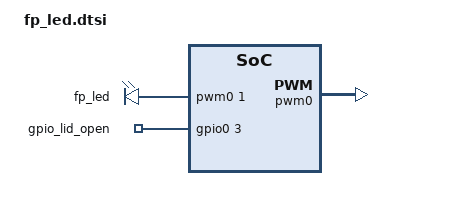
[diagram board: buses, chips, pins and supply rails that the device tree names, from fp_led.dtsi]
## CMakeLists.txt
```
# Copyright 2024 The ChromiumOS Authors
# Use of this source code is governed by a BSD-style license that can be
# found in the LICENSE file.

cmake_minimum_required(VERSION 3.13.1)
find_package(Zephyr REQUIRED HINTS "${ZEPHYR_BASE}")
project(fpsensor_task_test)

target_include_directories(app PUBLIC ${PLATFORM_EC}/common)
zephyr_include_directories("${CMAKE_CURRENT_SOURCE_DIR}/include")

target_sources(app PRIVATE src/mock_fingerprint_algorithm.c)
target_sources_ifdef(CONFIG_LINK_TEST_SUITE_FINGERPRINT_CAPTURE app PRIVATE
	src/fpsensor_capture.cc)
target_sources_ifdef(CONFIG_LINK_TEST_SUITE_FINGERPRINT_ENROLL app PRIVATE
	src/fpsensor_enroll.cc)
target_sources_ifdef(CONFIG_LINK_TEST_SUITE_FINGERPRINT_FINGER_PRESENCE app PRIVATE
	src/fpsensor_finger_presence.cc)
target_sources_ifdef(CONFIG_LINK_TEST_SUITE_FINGERPRINT_GET_FRAME app PRIVATE
	src/fpsensor_get_frame.cc)
target_sources_ifdef(CONFIG_LINK_TEST_SUITE_FINGERPRINT_INIT app PRIVATE
	src/fpsensor_init.cc)
target_sources_ifdef(CONFIG_LINK_TEST_SUITE_FINGERPRINT_MATCH app PRIVATE
	src/fpsensor_match.cc)
target_sources_ifdef(CONFIG_LINK_TEST_SUITE_FINGERPRINT_SHIM app PRIVATE
	src/fpsensor_shim.cc)
target_sources_ifdef(CONFIG_LINK_TEST_SUITE_FINGERPRINT_STATE app PRIVATE
	src/fpsensor_state.cc)
target_sources_ifdef(CONFIG_LINK_TEST_SUITE_FINGERPRINT_TEMPLATE app PRIVATE
	src/fpsensor_template.cc
	${PLATFORM_EC}/zephyr/mock/fpsensor_crypto_mock.cc)
target_sources_ifdef(CONFIG_LINK_TEST_SUITE_FINGERPRINT_UTILS app PRIVATE
	src/fpsensor_utils.cc)
target_sources_ifdef(CONFIG_LINK_TEST_SUITE_FINGERPRINT_DEBUG app PRIVATE
	src/fpsensor_debug.cc)
target_sources_ifdef(CONFIG_LINK_TEST_SUITE_FINGERPRINT_COMMANDS app PRIVATE
	src/fpsensor_vendor_command.cc)
target_sources_ifdef(CONFIG_LINK_TEST_SUITE_FINGERPRINT_ASCP app PRIVATE
	src/fpsensor_ascp.cc)
target_sources_ifdef(CONFIG_LINK_TEST_SUITE_FINGERPRINT_IMAGE_FRAME_PARAMS app PRIVATE
	src/fpsensor_image_frame_params.cc)
target_sources_ifdef(CONFIG_LINK_TEST_SUITE_FINGERPRINT_BTN_IGN_OUT app PRIVATE
	src/fpsensor_btn_ign_out.cc)
target_sources_ifdef(CONFIG_LINK_TEST_SUITE_FINGERPRINT_LED app PRIVATE
	src/fpsensor_led.cc)
target_sources_ifdef(CONFIG_LINK_TEST_SUITE_FINGERPRINT_AUTH_COMMANDS app PRIVATE
	src/fpsensor_auth_commands.cc)
target_sources_ifdef(CONFIG_NPCX_OTP_KEY app PRIVATE
	${PLATFORM_EC}/zephyr/shim/chip/npcx/otp_key.c
	${PLATFORM_EC}/zephyr/mock/otpi_mock.c)

add_subdirectory(${PLATFORM_EC}/zephyr/test/test_utils test_utils)
```

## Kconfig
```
# Copyright 2024 The ChromiumOS Authors
# Use of this source code is governed by a BSD-style license that can be
# found in the LICENSE file.

config LINK_TEST_SUITE_FINGERPRINT_CAPTURE
	bool "Link fingerprint capture tests"
	help
	  Link and execute fingerprint subsystem tests that focus
	  on finger capture.

config LINK_TEST_SUITE_FINGERPRINT_ENROLL
	bool "Link fingerprint enroll tests"
	help
	  Link and execute fingerprint subsystem tests that focus
	  on template enrollment.

config LINK_TEST_SUITE_FINGERPRINT_FINGER_PRESENCE
	bool "Link fingerprint finger presence tests"
	help
	  Link and execute fingerprint subsystem tests that focus
	  on finger presence.

config LINK_TEST_SUITE_FINGERPRINT_GET_FRAME
	bool "Link fingerprint get frame tests"
	help
	  Link and execute fingerprint subsystem tests that focus
	  on the get_frame functionality, verifying memory bounds,
	  buffer offsets, and hardware state.

config LINK_TEST_SUITE_FINGERPRINT_INIT
	bool "Link fingerprint init tests"
	help
	  Link and execute fingerprint subsystem tests that focus
	  on initializing TPM seed and context.

config LINK_TEST_SUITE_FINGERPRINT_MATCH
	bool "Link fingerprint match tests"
	help
	  Link and execute fingerprint subsystem tests that focus
	  on finger matching.

config LINK_TEST_SUITE_FINGERPRINT_SHIM
	bool "Link fingerprint shim tests"
	help
	  Link and execute fingerprint subsystem tests that focus
	  on fpsensor shim.

config LINK_TEST_SUITE_FINGERPRINT_STATE
	bool "Link fingerprint state tests"
	help
	  Link and execute fingerprint subsystem tests that focus
	  on fpsensor state.

config LINK_TEST_SUITE_FINGERPRINT_TEMPLATE
	bool "Link fingerprint template tests"
	help
	  Link and execute fingerprint subsystem tests that focus
	  on finger templates.

config LINK_TEST_SUITE_FINGERPRINT_UTILS
	bool "Link fingerprint utils tests"
	help
	  Link and execute fingerprint subsystem tests that focus
	  on finger utils.

config LINK_TEST_SUITE_FINGERPRINT_DEBUG
	bool "Link fingerprint debug tests"
	help
	  Link and execute fingerprint subsystem tests that focus
	  on finger debug.

config LINK_TEST_SUITE_FINGERPRINT_COMMANDS
	bool "Link fingerprint commands tests"
	help
	  Link and execute fingerprint subsystem tests that focus
	  on fingerprint host and console commands.

config LINK_TEST_SUITE_FINGERPRINT_ASCP
	bool "Link fingerprint ASCP tests"
	help
	  Link and execute fingerprint subsystem tests that focus
	  on ASCP.

config LINK_TEST_SUITE_FINGERPRINT_FRAME_SIZE
	bool "Link fingerprint frame size tests"
	help
	  Link and execute fingerprint subsystem tests that focus
	  on finger frame size.

config LINK_TEST_SUITE_FINGERPRINT_BTN_IGN_OUT
	bool "Link fingerprint btn ign out tests"
	help
	  Link and execute fingerprint subsystem tests that focus
	  on btn ign out.

config LINK_TEST_SUITE_FINGERPRINT_LED
	bool "Link fingerprint led tests"
	select HAS_PM
	help
	  Link and execute fingerprint subsystem tests that focus
	  on led.

config LINK_TEST_SUITE_FINGERPRINT_AUTH_COMMANDS
	bool "Link fingerprint auth commands tests"
	help
	  Link and execute fingerprint subsystem tests that focus
	  on fingerprint auth commands.

config LINK_TEST_SUITE_FINGERPRINT_CRYPTO
	bool "Link fingerprint crypto tests"
	help
	  Link and execute fingerprint subsystem crypto tests.

config LINK_TEST_SUITE_FINGERPRINT_AUTH_CRYPTO_STATEFUL
	bool "Link fingerprint stateful auth crypto tests"
	help
	  Link and execute fingerprint stateful auth crypto tests.

config LINK_TEST_SUITE_FINGERPRINT_AUTH_CRYPTO_STATELESS
	bool "Link fingerprint stateless auth crypto tests"
	help
	  Link and execute fingerprint stateless auth crypto tests.

config OTP_KEY
	bool "Enable OTP key mock support"
	default n

config EC_HOST_CMD_HANDLER_TX_BUFFER_SIZE
	int "HC TX buffer size"
	default 544

source "Kconfig.zephyr"
```

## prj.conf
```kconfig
# Copyright 2024 The ChromiumOS Authors
# Use of this source code is governed by a BSD-style license that can be
# found in the LICENSE file.

CONFIG_TEST=y
CONFIG_ZTEST=y
CONFIG_EMUL=y
CONFIG_FLASH=y
CONFIG_GPIO=y

CONFIG_UART_NATIVE_PTY_0_ON_STDINOUT=y

CONFIG_CPP=y
CONFIG_STD_CPP23=y
CONFIG_REQUIRES_FULL_LIBCPP=y

CONFIG_CROS_EC=y
CONFIG_PLATFORM_EC=y
CONFIG_SHIMMED_TASKS=y

CONFIG_COMMON_LIBC_MALLOC=y
CONFIG_COMMON_LIBC_MALLOC_ARENA_SIZE=2048
CONFIG_BORINGSSL_CRYPTO=y

CONFIG_PLATFORM_EC_RANDOM=y
CONFIG_PLATFORM_EC_FINGERPRINT=y
CONFIG_PLATFORM_EC_ROLLBACK=y
CONFIG_PLATFORM_EC_ROLLBACK_UPDATE=y
CONFIG_PLATFORM_EC_ROLLBACK_SECRET_SIZE=32
CONFIG_PLATFORM_EC_SHA256_SW=y
CONFIG_PLATFORM_EC_SHA256_UNROLLED=y
CONFIG_PLATFORM_EC_BACKLIGHT_LID=n
CONFIG_PLATFORM_EC_CONSOLE_CMD_CHARGEN=n
CONFIG_PLATFORM_EC_SWITCH=n
CONFIG_PLATFORM_EC_FLASH_SIZE_BYTES=0x200000
CONFIG_PLATFORM_EC_HOSTCMD=y

CONFIG_FINGERPRINT_SUBSYSTEM=y
CONFIG_FINGERPRINT_SENSOR=y

CONFIG_FP_ALGORITHM_TEMPLATE_SIZE=32
```

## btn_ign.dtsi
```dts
/* Copyright 2026 The ChromiumOS Authors
 * Use of this source code is governed by a BSD-style license that can be
 * found in the LICENSE file.
 */

#include "boards/native_sim.overlay"

/ {
	aliases {
		gpio-btn-ign-out = &gpio_btn_ign_out;
	};

	gpio-outputs {
		compatible = "gpio-leds";

		gpio_btn_ign_out: gpio_btn_ign_out {
			gpios = <&gpio0 3 GPIO_ACTIVE_HIGH>;
		};
	};
};
```

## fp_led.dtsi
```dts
/* Copyright 2026 The ChromiumOS Authors
 * Use of this source code is governed by a BSD-style license that can be
 * found in the LICENSE file.
 */

#include "boards/native_sim.overlay"
#include <zephyr/dt-bindings/pwm/pwm.h>

/{
	pwm0: pwm@6 {
		compatible = "cros,pwm-mock";
		reg = <6 2>;
		#pwm-cells = <3>;
		status = "okay";
	};

	pwmleds {
		compatible = "pwm-leds";

		fp_led: fp_led {
			pwms = <&pwm0 1 PWM_MSEC(20) PWM_POLARITY_NORMAL>;
		};
	};

	gpio-keys {
		compatible = "gpio-keys";

		gpio_lid_open: gpio_lid_open {
			gpios = <&gpio0 3 (GPIO_PULL_UP | GPIO_ACTIVE_HIGH)>;
		};
	};

	power-states {
		suspend_to_idle: suspend_to_idle {
			compatible = "zephyr,power-state";
			power-state-name = "suspend-to-idle";
			substate-id = <0>;
			min-residency-us = <500>;
		};
	};

	aliases {
		pwm-fp-led = &fp_led;
		gpio-lid-open = &gpio_lid_open;
	};
};
```

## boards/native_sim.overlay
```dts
/* Copyright 2023 The ChromiumOS Authors
 * Use of this source code is governed by a BSD-style license that can be
 * found in the LICENSE file.
 */

#include <board-overlays/native_sim.dts>
#include <dt-bindings/gpio_defines.h>
#include <cros/binman.dtsi>

/* RAW image includes additional metadata */
#define FP_SIMULATOR_RAW_IMAGE_PROPS \
	width = <160>; \
	height = <160>; \
	bits-per-pixel = <8>; \
	frame-size = <26260>; \
	image-data-offset-bytes = <400>; \
	v4l2-pixel-format = "V4L2_PIX_FMT_GREY";

/* REAL image is just pixel data (160 * 160) */
#define FP_SIMULATOR_REAL_IMAGE_PROPS \
	width = <160>; \
	height = <160>; \
	bits-per-pixel = <8>; \
	/* Sensor real image size: (160*160) */ \
	frame-size = <25600>; \
	image-data-offset-bytes = <400>; \
	v4l2-pixel-format = "V4L2_PIX_FMT_GREY";

/ {
	chosen {
		cros-ec,flash-controller = &cros_flash;
		cros-fp,fingerprint-sensor = &fpsensor_sim;
	};

	aliases {
		gpio-wp = &ec_wp_l;
	};

	named-gpios {
		compatible = "named-gpios";

		ec_wp_l: write-protect {
			gpios = <&gpio0 0 GPIO_INPUT>;
		};

		fp_sensor_sel: fp_sensor_sel {
			gpios = <&gpio0 1 GPIO_INPUT>;
		};

		div_highside: div_highside {
			gpios = <&gpio0 2 GPIO_OUTPUT_HIGH>;
		};

		gpio_btn_ign_out: gpio_btn_ign_out {
			gpios = <&gpio0 3 GPIO_OUTPUT_INACTIVE>;
		};
	};

	cros_flash: cros-flash {
		compatible = "cros-ec,flash-emul";
	};

	fpsensor_sim: fpsensor-sim {
		compatible = "cros-ec,fingerprint-sensor-sim";
		configs {
			compatible = "fingerprint-image-frame-params";
			config0 {
				FP_SIMULATOR_RAW_IMAGE_PROPS
				capture-type = "FINGERPRINT_CAPTURE_TYPE_VENDOR_FORMAT";
			};
			config1 {
				FP_SIMULATOR_REAL_IMAGE_PROPS
				capture-type = "FINGERPRINT_CAPTURE_TYPE_SIMPLE_IMAGE";
			};
			config2 {
				FP_SIMULATOR_REAL_IMAGE_PROPS
				capture-type = "FINGERPRINT_CAPTURE_TYPE_PATTERN0";
			};
			config3 {
				FP_SIMULATOR_REAL_IMAGE_PROPS
				capture-type = "FINGERPRINT_CAPTURE_TYPE_PATTERN1";
			};
			config4 {
				FP_SIMULATOR_RAW_IMAGE_PROPS
				capture-type = "FINGERPRINT_CAPTURE_TYPE_QUALITY_TEST";
			};
			config5 {
				FP_SIMULATOR_REAL_IMAGE_PROPS
				capture-type = "FINGERPRINT_CAPTURE_TYPE_RESET_TEST";
			};
		};
	};
};

&gpio0 {
	ngpios = <4>;
};

&flash0 {
	partitions {
		compatible = "fixed-partitions";
		#address-cells = <1>;
		#size-cells = <1>;

		/* Rollback region must have erase unit size. */
		rollback0: partition@100000 {
			label = "rollback0";
			reg = <0x100000 DT_SIZE_K(4)>;
		};

		rollback1: partition@101000 {
			label = "rollback1";
			reg = <0x101000 DT_SIZE_K(4)>;
		};
	};
};
```

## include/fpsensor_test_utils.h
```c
/* Copyright 2026 The ChromiumOS Authors
 * Use of this source code is governed by a BSD-style license that can be
 * found in the LICENSE file.
 */

#ifndef PLATFORM_EC_ZEPHYR_TEST_FINGERPRINT_TASK_INCLUDE_FPSENSOR_TEST_UTILS_H_
#define PLATFORM_EC_ZEPHYR_TEST_FINGERPRINT_TASK_INCLUDE_FPSENSOR_TEST_UTILS_H_

#include <zephyr/devicetree.h>
#include <zephyr/kernel.h>
#include <zephyr/sys/printk.h>
#include <zephyr/sys/util.h>
#include <zephyr/ztest_assert.h>

#include <algorithm>
#include <array>
#include <drivers/fingerprint.h>
#include <drivers/fingerprint_sim.h>
#include <flash.h>
#include <fpsensor/fpsensor.h>
#include <fpsensor/fpsensor_image_frame_params.h>
#include <fpsensor/fpsensor_modes.h>
#include <host_command.h>
#include <rollback.h>
#include <rollback_private.h>
#include <string_view>
#include <utility>

class FpSimulator {
    public:
	constexpr explicit FpSimulator(const device *dev) noexcept : dev_(dev)
	{
	}

	constexpr operator const device *() const noexcept
	{
		return dev_;
	}

	template <typename Fn> void update(Fn &&mutate) const
	{
		fingerprint_sensor_state state{};
		fingerprint_get_state(dev_, &state);
		mutate(state);
		fingerprint_set_state(dev_, &state);
	}

	void reset() const
	{
		fingerprint_sensor_state state = {
			.bad_pixels = 0,
			.maintenance_ran = false,
			.detect_mode = false,
			.low_power_mode = false,
			.finger_state = FINGERPRINT_FINGER_STATE_NONE,
			.init_result = 0,
			.deinit_result = 0,
			.config_result = 0,
			.get_info_result = 0,
			.acquire_image_result = FINGERPRINT_SENSOR_SCAN_GOOD,
			.last_acquire_image_mode = -1,
		};
		fingerprint_set_state(dev_, &state);
	}

    private:
	const device *dev_;
};

inline constexpr FpSimulator fp_sim{ DEVICE_DT_GET(
	DT_CHOSEN(cros_fp_fingerprint_sensor)) };

inline constexpr size_t kImageSize = MAX_FROM_LIST(
	LISTIFY(NUM_IMAGE_CAPTURE_TYPES, FINGERPRINT_SENSOR_FRAME_SIZE, (, ),
		DT_CHOSEN(cros_fp_fingerprint_sensor)));

inline constexpr uintptr_t kRollback0Addr =
	DT_REG_ADDR(DT_NODELABEL(rollback0));
inline constexpr size_t kRollback0Size = DT_REG_SIZE(DT_NODELABEL(rollback0));
inline constexpr uintptr_t kRollback1Addr =
	DT_REG_ADDR(DT_NODELABEL(rollback1));
inline constexpr size_t kRollback1Size = DT_REG_SIZE(DT_NODELABEL(rollback1));

/* The fake TPM seed is "very_secret_32_bytes_of_tpm_seed" */
inline constexpr std::array<uint8_t, FP_CONTEXT_TPM_BYTES> kDefaultTpmSeed = {
	0x76, 0x65, 0x72, 0x79, 0x5f, 0x73, 0x65, 0x63, 0x72, 0x65, 0x74,
	0x5f, 0x33, 0x32, 0x5f, 0x62, 0x79, 0x74, 0x65, 0x73, 0x5f, 0x6f,
	0x66, 0x5f, 0x74, 0x70, 0x6d, 0x5f, 0x73, 0x65, 0x65, 0x64
};

/* The fake UserID is "i_m_a_fake_user_id_used_for_test" */
inline constexpr std::array<uint32_t, FP_CONTEXT_USERID_WORDS> kDefaultUserId = {
	0x5f6d5f69, 0x61665f61, 0x755f656b, 0x5f726573,
	0x755f6469, 0x5f646573, 0x5f726f66, 0x74736574
};

template <typename Fn> inline void update_sim_state(Fn &&mutate)
{
	fp_sim.update(std::forward<Fn>(mutate));
}

inline void reset_sim_state()
{
	fp_sim.reset();
}

template <typename PreEntropyFn = decltype([] {})>
inline void init_test_rollback(PreEntropyFn &&pre_entropy = {})
{
	static constexpr std::string_view kEntropy = "some_rollback_entropy";
	const rollback_data data = {
		.id = 0,
		.rollback_min_version = 0,
#ifdef CONFIG_PLATFORM_EC_ROLLBACK_SECRET_SIZE
		.secret = { 0 },
#endif
		.cookie = CROS_EC_ROLLBACK_COOKIE,
	};

	zassert_ok(crec_flash_erase(kRollback0Addr, kRollback0Size));
	zassert_ok(crec_flash_write(kRollback0Addr, sizeof(data),
				    reinterpret_cast<const char *>(&data)));

	zassert_ok(crec_flash_erase(kRollback1Addr, kRollback1Size));
	zassert_ok(crec_flash_write(kRollback1Addr, sizeof(data),
				    reinterpret_cast<const char *>(&data)));

	pre_entropy();

	rollback_add_entropy(reinterpret_cast<const uint8_t *>(kEntropy.data()),
			     kEntropy.size());
}

inline uint32_t get_fp_mode()
{
	ec_params_fp_mode params = {
		.mode = FP_MODE_DONT_CHANGE,
	};
	ec_response_fp_mode response{};
	zassert_ok(ec_cmd_fp_mode(nullptr, &params, &response));
	return response.mode;
}

inline int get_fp_info_v3(FpSensorInfoBuffer &buf,
			  size_t size = sizeof(FpSensorInfoBuffer))
{
	return ec_cmd_fp_info_v3(nullptr, &buf.header, size);
}

inline uint32_t set_fp_mode(uint32_t mode)
{
	ec_params_fp_mode params = {
		.mode = mode,
	};
	ec_response_fp_mode response{};
	zassert_ok(ec_cmd_fp_mode(nullptr, &params, &response));
	k_msleep(1);
	return response.mode;
}

inline void set_default_tpm_seed()
{
	ec_params_fp_seed fp_seed_params = {
		.struct_version = FP_TEMPLATE_FORMAT_VERSION,
		.reserved = 0,
	};
	std::ranges::copy(kDefaultTpmSeed, fp_seed_params.seed);
	zassert_ok(ec_cmd_fp_seed(nullptr, &fp_seed_params));
}

inline void reset_test_fp_context(
	std::span<const uint32_t, FP_CONTEXT_USERID_WORDS> userid =
		kDefaultUserId)
{
	ec_params_fp_context_v1 fp_context_params = {
		.action = FP_CONTEXT_ASYNC,
	};
	std::ranges::copy(userid, fp_context_params.userid);
	zassert_ok(ec_cmd_fp_context_v1(nullptr, &fp_context_params));
	k_msleep(1);

	fp_context_params.action = FP_CONTEXT_GET_RESULT;
	zassert_ok(ec_cmd_fp_context_v1(nullptr, &fp_context_params));
}

extern "C" inline ec_status test_send_host_command(int command, int version,
						   const void *params,
						   int params_size, void *resp,
						   int resp_size)
{
	host_cmd_handler_args args{};

	args.command = command;
	args.version = version;
	args.params = params;
	args.params_size = params_size;
	args.response = resp;
	args.response_max = resp_size;
	args.response_size = 0;

	return static_cast<ec_status>(host_command_process(&args));
}

template <typename Params, typename Resp>
inline ec_status send_host_cmd(int command, int version, const Params &params,
			       Resp &resp)
{
	return test_send_host_command(command, version, &params, sizeof(params),
				      &resp, sizeof(resp));
}

template <typename Params>
inline ec_status send_host_cmd_req(int command, int version,
				   const Params &params)
{
	return test_send_host_command(command, version, &params, sizeof(params),
				      nullptr, 0);
}

template <typename Resp>
inline ec_status send_host_cmd_resp(int command, int version, Resp &resp)
{
	return test_send_host_command(command, version, nullptr, 0, &resp,
				      sizeof(resp));
}

#define FP_SIMULATOR_IMAGE_FRAME_PARAM_INITIALIZER(idx, node_id)            \
	{                                                                   \
		.frame_size = FINGERPRINT_SENSOR_FRAME_SIZE(idx, node_id),  \
		.image_data_offset_bytes =                                  \
			FINGERPRINT_SENSOR_IMAGE_OFFSET(idx, node_id),      \
		.pixel_format =                                             \
			FINGERPRINT_SENSOR_V4L2_PIXEL_FORMAT(idx, node_id), \
		.width = FINGERPRINT_SENSOR_RES_X(idx, node_id),            \
		.height = FINGERPRINT_SENSOR_RES_Y(idx, node_id),           \
		.bpp = FINGERPRINT_SENSOR_RES_BPP(idx, node_id),            \
		.fp_capture_type =                                          \
			FINGERPRINT_SENSOR_CAPTURE_TYPE(idx, node_id),      \
		.reserved = 0,                                              \
	}

#if DT_NODE_EXISTS(DT_NODELABEL(fpsensor_sim))
inline constexpr auto kDefaultSimImageFrameParams =
	std::to_array<fingerprint_image_frame_params>(
		{ LISTIFY(NUM_IMAGE_CAPTURE_TYPES,
			  FP_SIMULATOR_IMAGE_FRAME_PARAM_INITIALIZER, (, ),
			  DT_NODELABEL(fpsensor_sim)) });
#endif

class FpImageFrameParamsCacheTestHelper {
    public:
	FpImageFrameParamsCacheTestHelper() = delete;

	static bool set_frame_size(FpImageFrameParamsCache &cache,
				   fp_capture_type capture_type, uint32_t size)
	{
		const auto valid_type = FpCaptureType::create(capture_type);
		if (!valid_type.has_value()) {
			printk("Error: Invalid capture type %d\n",
			       capture_type);
			return false;
		}
		cache.frame_params_[valid_type->raw()].frame_size_bytes = size;
		return true;
	}
};

#endif /* PLATFORM_EC_ZEPHYR_TEST_FINGERPRINT_TASK_INCLUDE_FPSENSOR_TEST_UTILS_H_ \
	*/
```

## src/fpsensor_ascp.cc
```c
/* Copyright 2026 The ChromiumOS Authors
 * Use of this source code is governed by a BSD-style license that can be
 * found in the LICENSE file.
 */

#include "common.h"
#include "console.h"
#include "fpsensor/fpsensor_auth_crypto.h"
#include "fpsensor_test_utils.h"
#include "openssl/mem.h"
#include "system.h"

#include <zephyr/drivers/emul.h>
#include <zephyr/fff.h>
#include <zephyr/ztest.h>

#include <algorithm>
#include <array>
extern "C" {
#include <ascp/ascp.h>
}
#include <ec_commands.h>
#include <fpsensor/fpsensor.h>
#include <fpsensor/fpsensor_state.h>
#include <fpsensor/fpsensor_state_driver.h>
#include <fpsensor/fpsensor_utils.h>
#include <fpsensor_driver.h>
#include <host_command.h>
#include <mkbp_event.h>
#include <ranges>

FAKE_VALUE_FUNC(int, mkbp_send_event, uint8_t);

namespace
{

constexpr std::array<uint8_t, FP_ELLIPTIC_CURVE_PRIVATE_KEY_LEN> kSkF = {
	0x64, 0xfb, 0xd5, 0x8f, 0x6b, 0x57, 0x2a, 0x41, 0xef, 0x00, 0x0e,
	0x18, 0x92, 0xf8, 0xb5, 0x52, 0xc7, 0x41, 0x34, 0x35, 0xb1, 0xce,
	0x7c, 0x11, 0xfc, 0xf5, 0xa5, 0x94, 0x97, 0xaa, 0xc4, 0x91
};

constexpr std::array<uint8_t, FP_ASCP_KEY_SIZE> kPkF = {
	0x04, 0x48, 0x04, 0x5c, 0x21, 0x5b, 0x8d, 0x9b, 0x23, 0x31, 0x95,
	0x0e, 0x2a, 0x8d, 0x8f, 0x26, 0x22, 0x66, 0xe9, 0x59, 0xc2, 0x37,
	0xc9, 0x4f, 0x94, 0x73, 0x27, 0xc2, 0xb1, 0x11, 0xa0, 0x01, 0x78,
	0x13, 0x2f, 0x08, 0x9e, 0x94, 0xe7, 0x6d, 0x58, 0x76, 0xa1, 0x1a,
	0x20, 0xda, 0x0c, 0xc1, 0xef, 0x91, 0xaf, 0xb1, 0x5d, 0x48, 0x81,
	0x1b, 0x6b, 0xe1, 0x6e, 0xc0, 0xd5, 0xfb, 0x9d, 0x69, 0x82
};

constexpr std::array<uint8_t, FP_ELLIPTIC_CURVE_PRIVATE_KEY_LEN> kSkG = {
	0x2e, 0xdd, 0x7a, 0x67, 0x2f, 0x22, 0x21, 0x5c, 0x23, 0x80, 0xf0,
	0x80, 0x29, 0x5c, 0x6d, 0x95, 0xe9, 0x0b, 0x31, 0x9c, 0x17, 0xc1,
	0xc6, 0xcc, 0xe3, 0xbe, 0x9b, 0x7c, 0xd7, 0x2a, 0x18, 0x3f
};

constexpr std::array<uint8_t, FP_ASCP_KEY_SIZE> kPkG = {
	0x04, 0x65, 0xf5, 0xd4, 0x79, 0x82, 0x7e, 0xc1, 0xaf, 0x28, 0x2e,
	0x4b, 0xd0, 0xa6, 0xcb, 0xf4, 0xf4, 0xf5, 0x16, 0x63, 0xa6, 0x85,
	0x40, 0xdc, 0xa4, 0x26, 0xe8, 0x63, 0xc3, 0xa8, 0x52, 0xd3, 0x25,
	0x42, 0x8d, 0xd4, 0x7d, 0x85, 0x30, 0x6c, 0x16, 0x6e, 0x99, 0x24,
	0x65, 0x5c, 0x6d, 0x9b, 0x04, 0xfe, 0xfb, 0x83, 0x49, 0x9d, 0xa9,
	0x2a, 0xae, 0x75, 0x3e, 0x79, 0xdc, 0xa1, 0x80, 0x6e, 0x6e
};

std::array<uint8_t, FP_ELLIPTIC_CURVE_PRIVATE_KEY_LEN> ascp_get_sk_f_custom_sk_f;
int ascp_get_sk_f_custom_ret;

ec_params_fp_ascp_establish make_establish_params()
{
	ec_params_fp_ascp_establish params{};
	std::ranges::copy(kPkG, params.pk_g);
	return params;
}

void reset(void *data)
{
	ARG_UNUSED(data);

	ascp_get_sk_f_custom_ret = 0;
	ascp_get_sk_f_custom_sk_f = kSkF;
}

} /* namespace */

extern "C" int ascp_get_claim(ec_response_fp_ascp_claim *res)
{
	return EC_SUCCESS;
}

extern "C" int ascp_get_sk_f(uint8_t *buffer, size_t len)
{
	zassert_equal(len, FP_ELLIPTIC_CURVE_PRIVATE_KEY_LEN);
	if (ascp_get_sk_f_custom_ret != 0) {
		return ascp_get_sk_f_custom_ret;
	}
	std::ranges::copy(ascp_get_sk_f_custom_sk_f, buffer);
	return EC_SUCCESS;
}

ZTEST(hc_fp_ascp, test_fp_ascp_establish_ok)
{
	ec_params_fp_ascp_establish params = make_establish_params();

	zassert_equal(EC_RES_SUCCESS,
		      ec_cmd_fp_ascp_establish(nullptr, &params));

	const auto public_key = FpP256Key::from_uncompressed_point(kPkF);
	const auto private_key = FpP256Key::from_private_key(kSkG);
	zassert_true(public_key.has_value());
	zassert_true(private_key.has_value());

	const auto host_pairing_key =
		private_key->compute_shared_secret(*public_key);
	zassert_true(host_pairing_key.has_value());

	zassert_true(std::ranges::equal(
		*host_pairing_key, global_context.crypto.pairing_key.bytes()));
}

ZTEST(hc_fp_ascp, test_fp_ascp_establish_pk_g_first_not_ok)
{
	ec_params_fp_ascp_establish params = make_establish_params();
	params.pk_g[0] = 0x05;

	zassert_equal(EC_RES_INVALID_PARAM,
		      ec_cmd_fp_ascp_establish(nullptr, &params));
}

ZTEST(hc_fp_ascp, test_fp_ascp_establish_pk_g_later_not_ok)
{
	ec_params_fp_ascp_establish params = make_establish_params();
	params.pk_g[1] = 0x00;

	zassert_equal(EC_RES_INVALID_PARAM,
		      ec_cmd_fp_ascp_establish(nullptr, &params));
}

ZTEST(hc_fp_ascp, test_fp_ascp_establish_ascp_get_sk_f_not_ok)
{
	ec_params_fp_ascp_establish params = make_establish_params();
	ascp_get_sk_f_custom_ret = -1;

	zassert_equal(EC_RES_ERROR, ec_cmd_fp_ascp_establish(nullptr, &params));
}

ZTEST(hc_fp_ascp, test_fp_ascp_establish_sk_f_not_ok)
{
	ec_params_fp_ascp_establish params = make_establish_params();
	std::ranges::fill(ascp_get_sk_f_custom_sk_f, 0);

	zassert_equal(EC_RES_ERROR, ec_cmd_fp_ascp_establish(nullptr, &params));
}

ZTEST_SUITE(hc_fp_ascp, nullptr, nullptr, reset, reset, nullptr);
```

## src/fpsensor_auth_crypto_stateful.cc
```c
/* Copyright 2026 The ChromiumOS Authors
 * Use of this source code is governed by a BSD-style license that can be
 * found in the LICENSE file.
 */

#include "common.h"
#include "ec_commands.h"
#include "fpsensor/fpsensor_auth_crypto.h"
#include "fpsensor/fpsensor_state.h"
#include "mkbp_event.h"
#include "mock/otpi_mock.h"
#include "openssl/bn.h"
#include "openssl/ec.h"
#include "openssl/obj_mac.h"
#include "otp_key.h"

#include <assert.h>
#include <stdbool.h>
#include <string.h>

#include <zephyr/fff.h>
#include <zephyr/ztest.h>

FAKE_VALUE_FUNC(int, mkbp_send_event, uint8_t);

#include <algorithm>
#include <array>

constexpr std::array<uint8_t, 32> kFakeTpmSeed = {
	0xd9, 0x71, 0xaf, 0xc4, 0xcd, 0x36, 0xe3, 0x60, 0xf8, 0x5a, 0xa0,
	0xa6, 0x2c, 0xb3, 0xf5, 0xe2, 0xeb, 0xb9, 0xd8, 0x2f, 0xb5, 0x78,
	0x5c, 0x79, 0x82, 0xce, 0x06, 0x3f, 0xcc, 0x23, 0xb9, 0xe7,
};
static_assert(kFakeTpmSeed.size() == FP_CONTEXT_TPM_BYTES);

constexpr std::array<uint8_t, 32> kFakeUserId = {
	0x00, 0x01, 0x02, 0x03, 0x04, 0x05, 0x06, 0x07, 0x08, 0x09, 0x0a,
	0x0b, 0x0c, 0x0d, 0x0e, 0x0f, 0x10, 0x11, 0x12, 0x13, 0x14, 0x15,
	0x16, 0x17, 0x18, 0x19, 0x1a, 0x1b, 0x1c, 0x1d, 0x1e, 0x1f
};
static_assert(kFakeUserId.size() == FP_CONTEXT_USERID_BYTES);

void *setup_suite(void)
{
	if (IS_ENABLED(CONFIG_OTP_KEY)) {
		std::ranges::copy(default_fake_otp_key,
				  mock_otp.otp_key_buffer);
	}

	return NULL;
}

ZTEST_SUITE(fpsensor_auth_crypto_stateful, NULL, setup_suite, NULL, NULL, NULL);

ZTEST(fpsensor_auth_crypto_stateful, test_fp_encrypt_fail_size_mismatch)
{
	struct fp_auth_command_encryption_metadata info{};
	const std::array<uint8_t, 32> input = { 0, 1, 2, 3, 4, 5, 6, 7, 8, 9, 0,
						1, 2, 3, 4, 5, 6, 7, 8, 9, 0, 1,
						2, 3, 4, 5, 6, 7, 8, 9, 1, 2 };

	std::array<uint8_t, 31> too_small_buffer{};
	zassert_equal(encrypt_data(1, info, kFakeUserId, kFakeTpmSeed, input,
				   too_small_buffer),
		      EC_ERROR_OVERFLOW);

	std::array<uint8_t, 33> too_big_buffer{};
	zassert_equal(encrypt_data(1, info, kFakeUserId, kFakeTpmSeed, input,
				   too_big_buffer),
		      EC_ERROR_OVERFLOW);
}

ZTEST(fpsensor_auth_crypto_stateful, test_fp_decrypt_fail_size_mismatch)
{
	struct fp_auth_command_encryption_metadata info{};
	const std::array<uint8_t, 32> input = { 0, 1, 2, 3, 4, 5, 6, 7, 8, 9, 0,
						1, 2, 3, 4, 5, 6, 7, 8, 9, 0, 1,
						2, 3, 4, 5, 6, 7, 8, 9, 1, 2 };
	uint16_t version = 1;
	std::array<uint8_t, 32> enc_data{};

	zassert_equal(encrypt_data(version, info, kFakeUserId, kFakeTpmSeed,
				   input, enc_data),
		      EC_SUCCESS);

	std::array<uint8_t, 31> too_small_buffer{};
	zassert_equal(decrypt_data(info, kFakeUserId, kFakeTpmSeed, enc_data,
				   too_small_buffer),
		      EC_ERROR_OVERFLOW);

	std::array<uint8_t, 33> too_big_buffer{};
	zassert_equal(decrypt_data(info, kFakeUserId, kFakeTpmSeed, enc_data,
				   too_big_buffer),
		      EC_ERROR_OVERFLOW);
}

ZTEST(fpsensor_auth_crypto_stateful, test_fp_encrypt_decrypt_data)
{
	struct fp_auth_command_encryption_metadata info{};
	const std::array<uint8_t, 32> input = { 0, 1, 2, 3, 4, 5, 6, 7, 8, 9, 0,
						1, 2, 3, 4, 5, 6, 7, 8, 9, 0, 1,
						2, 3, 4, 5, 6, 7, 8, 9, 1, 2 };
	uint16_t version = 1;
	std::array<uint8_t, 32> enc_data{};

	zassert_equal(encrypt_data(version, info, kFakeUserId, kFakeTpmSeed,
				   input, enc_data),
		      EC_SUCCESS);

	zassert_equal(info.struct_version, version);

	/* The encrypted data should not be the same as the input. */
	zassert_false(memcmp(enc_data.data(), input.data(), enc_data.size()) ==
		      0);

	std::array<uint8_t, 32> output{};
	zassert_equal(decrypt_data(info, kFakeUserId, kFakeTpmSeed, enc_data,
				   output),
		      EC_SUCCESS);

	zassert_mem_equal(input.data(), output.data(), sizeof(input));
}

ZTEST(fpsensor_auth_crypto_stateful, test_fp_encrypt_decrypt_data_in_place)
{
	struct fp_auth_command_encryption_metadata info{};
	const std::array<uint8_t, 32> input = { 0, 1, 2, 3, 4, 5, 6, 7, 8, 9, 0,
						1, 2, 3, 4, 5, 6, 7, 8, 9, 0, 1,
						2, 3, 4, 5, 6, 7, 8, 9, 1, 2 };
	uint16_t version = 1;
	std::array<uint8_t, 32> data = input;

	zassert_equal(encrypt_data_in_place(version, info, kFakeUserId,
					    kFakeTpmSeed, data),
		      EC_SUCCESS);

	zassert_equal(info.struct_version, version);

	/* The encrypted data should not be the same as the input. */
	zassert_false(memcmp(data.data(), input.data(), data.size()) == 0);

	std::array<uint8_t, 32> output{};
	zassert_equal(decrypt_data(info, kFakeUserId, kFakeTpmSeed, data,
				   output),
		      EC_SUCCESS);

	zassert_mem_equal(input.data(), output.data(), sizeof(input));
}

ZTEST(fpsensor_auth_crypto_stateful, test_fp_encrypt_decrypt_pairing_key)
{
	struct fp_auth_command_encryption_metadata info{};
	const std::array<uint8_t, FP_PAIRING_KEY_LEN> input = {
		0, 1, 2, 3, 4, 5, 6, 7, 8, 9, 0, 1, 2, 3, 4, 5,
		6, 7, 8, 9, 0, 1, 2, 3, 4, 5, 6, 7, 8, 9, 1, 2
	};
	uint16_t version = 1;
	std::array<uint8_t, FP_PAIRING_KEY_LEN> enc_data{};

	zassert_equal(encrypt_pairing_key(version, info, input, enc_data),
		      EC_SUCCESS);

	zassert_equal(info.struct_version, version);

	/* The encrypted data should not be the same as the input. */
	zassert_false(memcmp(enc_data.data(), input.data(), enc_data.size()) ==
		      0);

	std::array<uint8_t, FP_PAIRING_KEY_LEN> output{};
	zassert_equal(decrypt_pairing_key(info, enc_data, output), EC_SUCCESS);

	zassert_mem_equal(input.data(), output.data(), sizeof(input));
}
```

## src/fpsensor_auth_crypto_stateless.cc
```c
/* Copyright 2026 The ChromiumOS Authors
 * Use of this source code is governed by a BSD-style license that can be
 * found in the LICENSE file.
 */

#include "common.h"
#include "crypto/elliptic_curve_key.h"
#include "ec_commands.h"
#include "fpsensor/fpsensor_auth_crypto.h"
#include "fpsensor/fpsensor_state.h"
#include "mkbp_event.h"
#include "openssl/aes.h"
#include "openssl/bn.h"
#include "openssl/ec.h"
#include "openssl/obj_mac.h"
#include "rollback.h"

#include <assert.h>

#include <zephyr/fff.h>
#include <zephyr/ztest.h>

FAKE_VALUE_FUNC(int, mkbp_send_event, uint8_t);

ZTEST_SUITE(fpsensor_auth_crypto_stateless, NULL, NULL, NULL, NULL, NULL);

ZTEST(fpsensor_auth_crypto_stateless, test_fp_create_ec_key_from_pubkey)
{
	fp_elliptic_curve_public_key pubkey = {
		.x = {
			0x85, 0xad, 0x35, 0x23, 0x05, 0x1e, 0x33, 0x3f,
			0xca, 0xa7, 0xea, 0xa5, 0x88, 0x33, 0x12, 0x95,
			0xa7, 0xb5, 0x98, 0x9f, 0x32, 0xef, 0x7d, 0xe9,
			0xf8, 0x70, 0x14, 0x5e, 0x89, 0xcb, 0xde, 0x1f,
		},
		.y = {
			0xd1, 0xdc, 0x91, 0xc6, 0xe6, 0x5b, 0x1e, 0x3c,
			0x01, 0x6c, 0xe6, 0x50, 0x25, 0x5d, 0x89, 0xcf,
			0xb7, 0x8d, 0x88, 0xb9, 0x0d, 0x09, 0x41, 0xf1,
			0x09, 0x4f, 0x61, 0x55, 0x6c, 0xc4, 0x96, 0x6b,
		},
	};

	bssl::UniquePtr<EC_KEY> key = create_ec_key_from_pubkey(pubkey);

	zassert_not_equal(key.get(), nullptr);
	zassert_equal(EC_KEY_check_key(key.get()), 1);
}

ZTEST(fpsensor_auth_crypto_stateless, test_fp_create_ec_key_from_pubkey_fail)
{
	fp_elliptic_curve_public_key pubkey = {
		.x = {},
		.y = {},
	};

	bssl::UniquePtr<EC_KEY> key = create_ec_key_from_pubkey(pubkey);

	zassert_equal(key.get(), nullptr);
}

ZTEST(fpsensor_auth_crypto_stateless, test_fp_create_pubkey_from_ec_key)
{
	fp_elliptic_curve_public_key pubkey = {
		.x = {
			0x85, 0xad, 0x35, 0x23, 0x05, 0x1e, 0x33, 0x3f,
			0xca, 0xa7, 0xea, 0xa5, 0x88, 0x33, 0x12, 0x95,
			0xa7, 0xb5, 0x98, 0x9f, 0x32, 0xef, 0x7d, 0xe9,
			0xf8, 0x70, 0x14, 0x5e, 0x89, 0xcb, 0xde, 0x1f,
		},
		.y = {
			0xd1, 0xdc, 0x91, 0xc6, 0xe6, 0x5b, 0x1e, 0x3c,
			0x01, 0x6c, 0xe6, 0x50, 0x25, 0x5d, 0x89, 0xcf,
			0xb7, 0x8d, 0x88, 0xb9, 0x0d, 0x09, 0x41, 0xf1,
			0x09, 0x4f, 0x61, 0x55, 0x6c, 0xc4, 0x96, 0x6b,
		},
	};

	bssl::UniquePtr<EC_KEY> key = create_ec_key_from_pubkey(pubkey);

	zassert_not_equal(key.get(), nullptr);
	zassert_equal(EC_KEY_check_key(key.get()), 1);

	auto result = create_pubkey_from_ec_key(*key);
	zassert_true(result.has_value());

	zassert_mem_equal(result->x, pubkey.x, sizeof(pubkey.x));
	zassert_mem_equal(result->y, pubkey.y, sizeof(pubkey.y));
}

ZTEST(fpsensor_auth_crypto_stateless, test_fp_create_ec_key_from_privkey)
{
	std::array<uint8_t, 32> data = { 0, 1, 2, 3, 4, 5, 6, 7, 8, 9, 0,
					 1, 2, 3, 4, 5, 6, 7, 8, 9, 0, 1,
					 2, 3, 4, 5, 6, 7, 8, 9, 1, 2 };

	bssl::UniquePtr<EC_KEY> key =
		create_ec_key_from_privkey(data.data(), data.size());

	zassert_not_equal(key.get(), nullptr);

	/* There is nothing to check for the private key. */
}

ZTEST(fpsensor_auth_crypto_stateless, test_fp_create_ec_key_from_privkey_fail)
{
	std::array<uint8_t, 1> data = {};

	bssl::UniquePtr<EC_KEY> key =
		create_ec_key_from_privkey(data.data(), data.size());

	zassert_equal(key.get(), nullptr);
}

ZTEST(fpsensor_auth_crypto_stateless, test_fp_generate_ecdh_shared_secret)
{
	struct fp_elliptic_curve_public_key pubkey = {
		.x = {
			0x85, 0xad, 0x35, 0x23, 0x05, 0x1e, 0x33, 0x3f,
			0xca, 0xa7, 0xea, 0xa5, 0x88, 0x33, 0x12, 0x95,
			0xa7, 0xb5, 0x98, 0x9f, 0x32, 0xef, 0x7d, 0xe9,
			0xf8, 0x70, 0x14, 0x5e, 0x89, 0xcb, 0xde, 0x1f,
		},
		.y = {
			0xd1, 0xdc, 0x91, 0xc6, 0xe6, 0x5b, 0x1e, 0x3c,
			0x01, 0x6c, 0xe6, 0x50, 0x25, 0x5d, 0x89, 0xcf,
			0xb7, 0x8d, 0x88, 0xb9, 0x0d, 0x09, 0x41, 0xf1,
			0x09, 0x4f, 0x61, 0x55, 0x6c, 0xc4, 0x96, 0x6b,
		},
	};

	bssl::UniquePtr<EC_KEY> public_key = create_ec_key_from_pubkey(pubkey);

	zassert_not_equal(public_key.get(), nullptr);

	std::array<uint8_t, 32> privkey = { 1, 1, 2, 3, 4, 5, 6, 7, 8, 9, 0,
					    1, 2, 3, 4, 5, 6, 7, 8, 9, 0, 1,
					    2, 3, 4, 5, 6, 7, 8, 9, 1, 2 };

	bssl::UniquePtr<EC_KEY> private_key =
		create_ec_key_from_privkey(privkey.data(), privkey.size());

	zassert_not_equal(private_key.get(), nullptr);

	std::array<uint8_t, 32> shared_secret;
	zassert_equal(generate_ecdh_shared_secret(*private_key, *public_key,
						  shared_secret),
		      EC_SUCCESS);

	std::array<uint8_t, 32> expected_result = {
		0x46, 0x86, 0xca, 0x75, 0xce, 0xa1, 0xde, 0x23,
		0x48, 0xb3, 0x0b, 0xfc, 0xd7, 0xbe, 0x7a, 0xa0,
		0x33, 0x17, 0x6c, 0x97, 0xc6, 0xa7, 0x70, 0x7c,
		0xd4, 0x2c, 0xfd, 0xc0, 0xba, 0xc1, 0x47, 0x01,
	};

	zassert_mem_equal(shared_secret.data(), expected_result.data(),
			  shared_secret.size());
}

ZTEST(fpsensor_auth_crypto_stateless,
      test_fp_generate_ecdh_shared_secret_without_kdf)
{
	struct fp_elliptic_curve_public_key pubkey = {
		.x = {
			0x85, 0xad, 0x35, 0x23, 0x05, 0x1e, 0x33, 0x3f,
			0xca, 0xa7, 0xea, 0xa5, 0x88, 0x33, 0x12, 0x95,
			0xa7, 0xb5, 0x98, 0x9f, 0x32, 0xef, 0x7d, 0xe9,
			0xf8, 0x70, 0x14, 0x5e, 0x89, 0xcb, 0xde, 0x1f,
		},
		.y = {
			0xd1, 0xdc, 0x91, 0xc6, 0xe6, 0x5b, 0x1e, 0x3c,
			0x01, 0x6c, 0xe6, 0x50, 0x25, 0x5d, 0x89, 0xcf,
			0xb7, 0x8d, 0x88, 0xb9, 0x0d, 0x09, 0x41, 0xf1,
			0x09, 0x4f, 0x61, 0x55, 0x6c, 0xc4, 0x96, 0x6b,
		},
	};

	bssl::UniquePtr<EC_KEY> public_key = create_ec_key_from_pubkey(pubkey);

	zassert_not_equal(public_key.get(), nullptr);

	std::array<uint8_t, 32> privkey = { 1, 1, 2, 3, 4, 5, 6, 7, 8, 9, 0,
					    1, 2, 3, 4, 5, 6, 7, 8, 9, 0, 1,
					    2, 3, 4, 5, 6, 7, 8, 9, 1, 2 };

	bssl::UniquePtr<EC_KEY> private_key =
		create_ec_key_from_privkey(privkey.data(), privkey.size());

	zassert_not_equal(private_key.get(), nullptr);

	std::array<uint8_t, 32> shared_secret;
	zassert_equal(generate_ecdh_shared_secret_without_kdf(
			      *private_key, *public_key, shared_secret),
		      EC_SUCCESS);

	std::array<uint8_t, 32> expected_result = {
		0x4d, 0x1f, 0x52, 0x54, 0xf8, 0x75, 0xf1, 0xee,
		0x00, 0x48, 0x6d, 0xe8, 0x50, 0x2f, 0xd6, 0xba,
		0xc4, 0x9e, 0xa4, 0xd3, 0x2c, 0x33, 0x50, 0x42,
		0x40, 0x91, 0xaf, 0xe8, 0xdd, 0x07, 0x90, 0x18,
	};

	zassert_mem_equal(shared_secret.data(), expected_result.data(),
			  shared_secret.size());
}

ZTEST(fpsensor_auth_crypto_stateless, test_fp_generate_session_key)
{
	std::array<uint8_t, 32> session_nonce = { 0, 1, 2, 3, 4, 5, 6, 7,
						  8, 9, 0, 1, 2, 3, 4, 5,
						  6, 7, 8, 9, 0, 1, 2, 3,
						  4, 5, 6, 7, 8, 9, 1, 2 };
	std::array<uint8_t, 32> gsc_nonce = { 1, 1, 2, 3, 4, 5, 6, 7, 8, 9, 0,
					      1, 2, 3, 4, 5, 6, 7, 8, 9, 0, 1,
					      2, 3, 4, 5, 6, 7, 8, 9, 1, 2 };
	std::array<uint8_t, 32> pairing_key = { 2, 1, 2, 3, 4, 5, 6, 7, 8, 9, 0,
						1, 2, 3, 4, 5, 6, 7, 8, 9, 0, 1,
						2, 3, 4, 5, 6, 7, 8, 9, 1, 2 };

	std::array<uint8_t, 32> gsc_session_key;

	zassert_equal(generate_session_key(session_nonce, gsc_nonce,
					   pairing_key, {}, gsc_session_key),
		      EC_SUCCESS);

	std::array<uint8_t, 32> expected_gsc_session_key = {
		0x50, 0x98, 0xde, 0xbd, 0x86, 0xb5, 0xc9, 0x2b,
		0x21, 0xea, 0x0e, 0x6f, 0x47, 0x25, 0x9d, 0x25,
		0x92, 0x09, 0x5c, 0xbe, 0x0a, 0x57, 0x8b, 0xc8,
		0x8c, 0x03, 0xa3, 0x2f, 0x39, 0x08, 0x02, 0x4b,
	};

	zassert_mem_equal(gsc_session_key.data(),
			  expected_gsc_session_key.data(),
			  gsc_session_key.size());
}

ZTEST(fpsensor_auth_crypto_stateless, test_fp_decrypt_data_with_session_key)
{
	std::array<uint8_t, 32> session_key = {
		0x1a, 0x1a, 0x3c, 0x33, 0x7f, 0xae, 0xf9, 0x3e,
		0xa8, 0x7c, 0xe4, 0xec, 0xd9, 0xff, 0x45, 0x8a,
		0xb6, 0x2f, 0x75, 0xd5, 0xea, 0x25, 0x93, 0x36,
		0x60, 0xf1, 0xab, 0xd2, 0xf4, 0x9f, 0x22, 0x89,
	};

	std::array<uint8_t, 12> nonce = {
		0, 1, 2, 3, 4, 5, 6, 7, 8, 9, 0, 1,
	};

	std::array<uint8_t, 32> input = {
		0x44, 0x13, 0xb6, 0xb2, 0xc9, 0x6d, 0x22, 0x40,
		0xdc, 0x5e, 0x70, 0x63, 0x26, 0xcc, 0x4b, 0x0e,
		0x25, 0xc6, 0xa0, 0x25, 0x9e, 0x9e, 0x8c, 0x91,
		0xf6, 0x88, 0xa9, 0x81, 0xdf, 0xc2, 0x5c, 0x4b,
	};

	std::array<uint8_t, 9> aad = {
		't', 'e', 's', 't', '_', 'd', 'a', 't', 'a',
	};

	std::array<uint8_t, 16> tag = {
		0xd7, 0x37, 0xe2, 0x08, 0x39, 0x48, 0x75, 0x9e,
		0x51, 0x20, 0x44, 0xc7, 0xeb, 0x78, 0xf4, 0x43,
	};

	std::array<uint8_t, 32> output{};

	zassert_equal(decrypt_data_with_session_key(session_key, input, output,
						    nonce, tag, aad),
		      EC_SUCCESS);

	std::array<uint8_t, 32> expected_output = { 0, 1, 2, 3, 4, 5, 6, 7,
						    8, 9, 0, 1, 2, 3, 4, 5,
						    6, 7, 8, 9, 0, 1, 2, 3,
						    4, 5, 6, 7, 8, 9, 1, 2 };

	zassert_mem_equal(output.data(), expected_output.data(), output.size());
}

ZTEST(fpsensor_auth_crypto_stateless,
      test_fp_decrypt_data_with_session_key_fail)
{
	std::array<uint8_t, 32> session_key = {
		0x1a, 0x1a, 0x3c, 0x33, 0x7f, 0xae, 0xf9, 0x3e,
		0xa8, 0x7c, 0xe4, 0xec, 0xd9, 0xff, 0x45, 0x8a,
		0xb6, 0x2f, 0x75, 0xd5, 0xea, 0x25, 0x93, 0x36,
		0x60, 0xf1, 0xab, 0xd2, 0xf4, 0x9f, 0x22, 0x89,
	};

	std::array<uint8_t, 12> nonce = {
		0, 1, 2, 3, 4, 5, 6, 7, 8, 9, 0, 1,
	};

	std::array<uint8_t, 32> input = {
		0x44, 0x13, 0xb6, 0xb2, 0xc9, 0x6d, 0x22, 0x40,
		0xdc, 0x5e, 0x70, 0x63, 0x26, 0xcc, 0x4b, 0x0e,
		0x25, 0xc6, 0xa0, 0x25, 0x9e, 0x9e, 0x8c, 0x91,
		0xf6, 0x88, 0xa9, 0x81, 0xdf, 0xc2, 0x5c, 0x4b,
	};

	std::array<uint8_t, 9> aad = {
		't', 'e', 's', 't', '_', 'd', 'a', 't', 'a',
	};

	std::array<uint8_t, 16> tag = {
		0xd7, 0x37, 0xe2, 0x08, 0x39, 0x48, 0x75, 0x9e,
		0x51, 0x20, 0x44, 0xc7, 0xeb, 0x78, 0xf4, 0x43,
	};

	/* Output buffer size does not match input buffer size. */
	std::array<uint8_t, 31> output{};

	zassert_equal(decrypt_data_with_session_key(session_key, input, output,
						    nonce, tag, aad),
		      EC_ERROR_OVERFLOW);
}
```

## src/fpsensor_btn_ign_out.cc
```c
/* Copyright 2026 The ChromiumOS Authors
 * Use of this source code is governed by a BSD-style license that can be
 * found in the LICENSE file.
 */

#include "compile_time_macros.h"
#include "fpsensor/fpsensor_btn_ign_out.h"

#include <zephyr/drivers/gpio.h>
#include <zephyr/drivers/gpio/gpio_emul.h>
#include <zephyr/fff.h>
#include <zephyr/ztest.h>

#include <cstdint>
#include <mkbp_event.h>

FAKE_VALUE_FUNC(int, mkbp_send_event, uint8_t);

static const struct gpio_dt_spec btn_ign_gpio =
	GPIO_DT_SPEC_GET(DT_ALIAS(gpio_btn_ign_out), gpios);

static void test_btn_ign_init(void *data)
{
	gpio_emul_input_set_dt(&btn_ign_gpio, 0);
}

static int btn_ign_get()
{
	return gpio_emul_output_get_dt(&btn_ign_gpio);
}

ZTEST_SUITE(fpsensor_btn_ign, NULL, NULL, test_btn_ign_init, NULL, NULL);

ZTEST(fpsensor_btn_ign, test_activate)
{
	fp_btn_ign_out::update(FpSensorMode::assume_valid(FP_MODE_MATCH));
	zassert_equal(btn_ign_get(), 1,
		      "GPIO pin should be high after activation");
}

ZTEST(fpsensor_btn_ign, test_deactivate)
{
	fp_btn_ign_out::update(FpSensorMode::assume_valid(
		FP_MODE_MATCH | FP_MODE_ENROLL_SESSION));
	k_sleep(K_MSEC(100));
	fp_btn_ign_out::update(FpSensorMode::assume_valid(0));

	k_sleep(K_MSEC(1000));
	zassert_equal(btn_ign_get(), 1, "GPIO should still be high");

	k_sleep(K_MSEC(1500));
	zassert_equal(btn_ign_get(), 0,
		      "GPIO pin should be low after deactivation");
}

ZTEST(fpsensor_btn_ign, test_activate_deactivate_consecutive_calls)
{
	fp_btn_ign_out::update(FpSensorMode::assume_valid(FP_MODE_MATCH));
	zassert_equal(btn_ign_get(), 1,
		      "GPIO should be high after first activate");

	fp_btn_ign_out::update(FpSensorMode::assume_valid(0));
	fp_btn_ign_out::update(
		FpSensorMode::assume_valid(FP_MODE_ENROLL_SESSION));

	k_sleep(K_MSEC(2500));
	zassert_equal(
		btn_ign_get(), 1,
		"GPIO should still be high due to cancelled deactivation");

	fp_btn_ign_out::update(FpSensorMode::assume_valid(0));
	k_sleep(K_MSEC(2500));
	zassert_equal(btn_ign_get(), 0,
		      "GPIO should be low after final deactivation");
}

ZTEST(fpsensor_btn_ign, test_deactivate_multiple_calls)
{
	fp_btn_ign_out::update(FpSensorMode::assume_valid(FP_MODE_CAPTURE));
	zassert_equal(btn_ign_get(), 1, "GPIO should be high after activate");

	fp_btn_ign_out::update(FpSensorMode::assume_valid(0));
	k_sleep(K_MSEC(1000));
	fp_btn_ign_out::update(FpSensorMode::assume_valid(0));

	k_sleep(K_MSEC(1500));
	zassert_equal(btn_ign_get(), 0,
		      "GPIO should be low 2s after first deactivation");
}
```

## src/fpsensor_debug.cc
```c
/* Copyright 2024 The ChromiumOS Authors
 * Use of this source code is governed by a BSD-style license that can be
 * found in the LICENSE file.
 */
#include "common.h"
#include "console.h"
#include "fpsensor_test_utils.h"
#include "system.h"

#include <zephyr/fff.h>
#include <zephyr/sys/util.h>
#include <zephyr/ztest.h>

#include <algorithm>
#include <array>
#include <cstdio>
#include <ec_commands.h>
#include <expected>
#include <fpsensor/fpsensor_modes.h>
#include <fpsensor/fpsensor_state_driver.h>
#include <fpsensor/fpsensor_utils.h>
#include <fpsensor_driver.h>
#include <mkbp_event.h>
#include <optional>
#include <rollback.h>

static_assert(sizeof(fp_image_frame_params_v2) ==
		      sizeof(fingerprint_image_frame_params),
	      "Frame param structures must be the same size");

namespace
{

int is_locked;

int run_console_cmd(const char *cmd, bool locked = false)
{
	is_locked = locked ? 1 : 0;
	return shell_execute_cmd(get_ec_shell(), cmd);
}

} /* namespace */

int system_is_locked()
{
	return is_locked;
}

FAKE_VALUE_FUNC(int, mkbp_send_event, uint8_t);

ZTEST_SUITE(fpsensor_debug, nullptr, nullptr, nullptr, nullptr, nullptr);

ZTEST(fpsensor_debug, test_console_fpinfo)
{
	zassert_equal(run_console_cmd("fpinfo"), EC_SUCCESS);
}

/* TODO(b/371647536): Add other tests of commands in fpsensor_debug to verify
 * entire handlers.
 */
ZTEST(fpsensor_debug, test_command_fpupload_success)
{
	zassert_equal(run_console_cmd("fpupload 52 image"), EC_SUCCESS);
}

ZTEST(fpsensor_debug, test_command_fpupload_system_is_locked)
{
	zassert_equal(run_console_cmd("fpupload 52 image", /*locked=*/true),
		      EC_ERROR_ACCESS_DENIED);
}

ZTEST(fpsensor_debug, test_command_fpupload_one_argument)
{
	zassert_equal(run_console_cmd("fpupload 52"), EC_ERROR_PARAM_COUNT);
}

ZTEST(fpsensor_debug, test_command_fpupload_three_arguments)
{
	zassert_equal(run_console_cmd("fpupload 52 image 78"),
		      EC_ERROR_PARAM_COUNT);
}

ZTEST(fpsensor_debug, test_command_fpupload_negative_offset)
{
	zassert_equal(run_console_cmd("fpupload -1 image"), EC_ERROR_PARAM1);
}

ZTEST(fpsensor_debug,
      test_command_fpupload_offset_equal_image_size_minus_image_offset)

{
	char console_input[] = "fpupload " STRINGIFY(UINT32_MAX) " image";
	snprintf(console_input, sizeof(console_input),
		 "fpupload %" PRIu32 " image",
		 FP_SENSOR_IMAGE_SIZE - FP_SENSOR_IMAGE_OFFSET);
	zassert_equal(run_console_cmd(console_input), EC_ERROR_PARAM1);
}

ZTEST(fpsensor_debug, test_command_fpupload_correct_uploaded_values)
{
	std::ranges::fill(fp_buffer, 0);
	zassert_equal(run_console_cmd("fpupload 0 f16e38"), EC_SUCCESS);
	zassert_equal(fp_buffer[FP_SENSOR_IMAGE_OFFSET], 241);
	zassert_equal(fp_buffer[FP_SENSOR_IMAGE_OFFSET + 1], 110);
	zassert_equal(fp_buffer[FP_SENSOR_IMAGE_OFFSET + 2], 56);
}

/* TODO(b/371647536): Add other tests of commands in fpsensor_debug to verify
 * entire handlers.
 */
ZTEST(fpsensor_debug, test_command_fpcapture_system_is_locked)
{
	zassert_equal(run_console_cmd("fpcapture", /*locked=*/true),
		      EC_ERROR_ACCESS_DENIED);
}

ZTEST(fpsensor_debug, test_command_fpcapture_mode_is_negative)
{
	zassert_equal(run_console_cmd("fpcapture -1"), EC_ERROR_PARAM1);
}

ZTEST(fpsensor_debug, test_command_fpcapture_mode_is_too_large)
{
	char console_input[32];
	snprintf(console_input, sizeof(console_input), "fpcapture %d",
		 FP_CAPTURE_TYPE_MAX);
	zassert_equal(run_console_cmd(console_input), EC_ERROR_PARAM1);
}

/* TODO(b/371647536): Add other tests of commands in fpsensor_debug to verify
 * entire handlers.
 */
ZTEST(fpsensor_debug, test_command_fpenroll)
{
	zassert_equal(run_console_cmd("fpenroll", /*locked=*/true),
		      EC_ERROR_ACCESS_DENIED);
	zassert_true(std::string_view(FpMkbpEvent(EC_MKBP_FP_ENROLL)
					      .enroll_error_name()) == "OK");
	zassert_true(
		std::string_view(FpMkbpEvent(EC_MKBP_FP_ENROLL |
					     EC_MKBP_FP_ERR_ENROLL_IMMOBILE)
					 .enroll_error_name()) == "Immobile");
}

std::expected<void, ec_error_list>
upload_pgm_image(std::span<const uint8_t> frame,
		 const fp_image_frame_params_v2 &image_frame_params);

ZTEST(fpsensor_debug, test_upload_pgm_image_wrong_bpp)
{
	std::array<uint8_t, 100> frame{};

	zassert_equal(upload_pgm_image(frame, { .bpp = 0 }).error(),
		      EC_ERROR_UNKNOWN);

	zassert_equal(upload_pgm_image(frame, { .bpp = 17 }).error(),
		      EC_ERROR_UNKNOWN);

	zassert_equal(upload_pgm_image(frame, { .bpp = 23 }).error(),
		      EC_ERROR_UNKNOWN);
}

ZTEST(fpsensor_debug, test_get_image_frame_params)
{
	constexpr auto kCaptureTypesArray = std::to_array(
		{ FP_CAPTURE_VENDOR_FORMAT, FP_CAPTURE_DEFECT_PXL_TEST,
		  FP_CAPTURE_ABNORMAL_TEST, FP_CAPTURE_NOISE_TEST,
		  FP_CAPTURE_SIMPLE_IMAGE, FP_CAPTURE_PATTERN0,
		  FP_CAPTURE_PATTERN1, FP_CAPTURE_QUALITY_TEST,
		  FP_CAPTURE_RESET_TEST, FP_CAPTURE_PATTERN2,
		  FP_CAPTURE_TYPE_MAX });

	for (fp_capture_type current_capture_type : kCaptureTypesArray) {
		const auto it = std::ranges::find(
			kDefaultSimImageFrameParams, current_capture_type,
			&fingerprint_image_frame_params::fp_capture_type);
		const fingerprint_image_frame_params *expected_params =
			(it != kDefaultSimImageFrameParams.end()) ? &(*it) :
								    nullptr;

		const auto capture_type =
			FpCaptureType::create(current_capture_type);
		const auto result = FpSensorInfoBuffer::find_capture_params(
			capture_type ? std::optional(*capture_type) :
				       std::nullopt);

		if (expected_params) {
			zassert_true(
				result.has_value(),
				"get_image_frame_params failed for capture type %d",
				current_capture_type);
			zassert_mem_equal(
				&(*result), expected_params,
				sizeof(fp_image_frame_params_v2),
				"Struct comparison failed for type %d",
				current_capture_type);
		} else {
			zassert_false(result.has_value());
			zassert_equal(
				result.error(), EC_ERROR_INVAL,
				"Expected EC_ERROR_INVAL (%d), but got %d for invalid type",
				EC_ERROR_INVAL, result.error());
		}
	}
}
```
